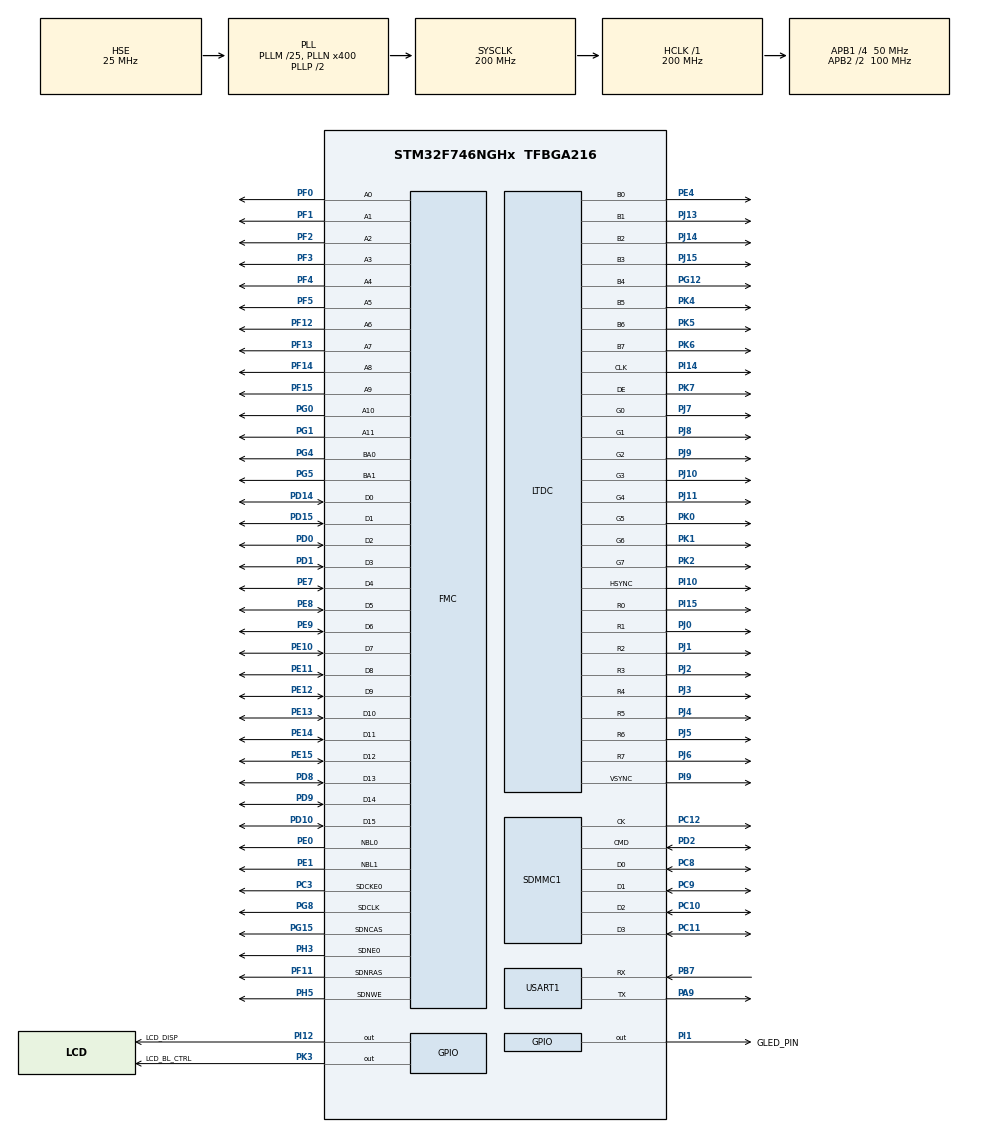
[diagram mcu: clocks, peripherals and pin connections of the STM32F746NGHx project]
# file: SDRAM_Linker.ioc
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CORTEX_M7.ART_ACCLERATOR_ENABLE=0
CORTEX_M7.AccessPermission-Cortex_Memory_Protection_Unit_Region0_Settings=MPU_REGION_FULL_ACCESS
CORTEX_M7.AccessPermission-Cortex_Memory_Protection_Unit_Region1_Settings=MPU_REGION_FULL_ACCESS
CORTEX_M7.AccessPermission-Cortex_Memory_Protection_Unit_Region2_Settings=MPU_REGION_FULL_ACCESS
CORTEX_M7.BaseAddress-Cortex_Memory_Protection_Unit_Region0_Settings=0xC0000000
CORTEX_M7.BaseAddress-Cortex_Memory_Protection_Unit_Region1_Settings=0xC0000000
CORTEX_M7.BaseAddress-Cortex_Memory_Protection_Unit_Region2_Settings=0xC0200000
CORTEX_M7.CPU_DCache=Enabled
CORTEX_M7.CPU_ICache=Enabled
CORTEX_M7.DisableExec-Cortex_Memory_Protection_Unit_Region1_Settings=MPU_INSTRUCTION_ACCESS_DISABLE
CORTEX_M7.DisableExec-Cortex_Memory_Protection_Unit_Region2_Settings=MPU_INSTRUCTION_ACCESS_DISABLE
CORTEX_M7.Enable-Cortex_Memory_Protection_Unit_Region0_Settings=MPU_REGION_ENABLE
CORTEX_M7.Enable-Cortex_Memory_Protection_Unit_Region1_Settings=MPU_REGION_ENABLE
CORTEX_M7.Enable-Cortex_Memory_Protection_Unit_Region2_Settings=MPU_REGION_ENABLE
CORTEX_M7.IsBufferable-Cortex_Memory_Protection_Unit_Region0_Settings=MPU_ACCESS_BUFFERABLE
CORTEX_M7.IsBufferable-Cortex_Memory_Protection_Unit_Region1_Settings=MPU_ACCESS_BUFFERABLE
CORTEX_M7.IsBufferable-Cortex_Memory_Protection_Unit_Region2_Settings=MPU_ACCESS_BUFFERABLE
CORTEX_M7.IsCacheable-Cortex_Memory_Protection_Unit_Region0_Settings=MPU_ACCESS_CACHEABLE
CORTEX_M7.IsCacheable-Cortex_Memory_Protection_Unit_Region1_Settings=MPU_ACCESS_CACHEABLE
CORTEX_M7.IsCacheable-Cortex_Memory_Protection_Unit_Region2_Settings=MPU_ACCESS_CACHEABLE
CORTEX_M7.MPU_Control=MPU_PRIVILEGED_DEFAULT
CORTEX_M7.Size-Cortex_Memory_Protection_Unit_Region0_Settings=MPU_REGION_SIZE_8MB
CORTEX_M7.Size-Cortex_Memory_Protection_Unit_Region1_Settings=MPU_REGION_SIZE_512KB
CORTEX_M7.Size-Cortex_Memory_Protection_Unit_Region2_Settings=MPU_REGION_SIZE_512KB
CORTEX_M7.TypeExtField-Cortex_Memory_Protection_Unit_Region0_Settings=MPU_TEX_LEVEL0
CORTEX_M7.TypeExtField-Cortex_Memory_Protection_Unit_Region1_Settings=MPU_TEX_LEVEL0
Dma.Request0=SDMMC1_RX
Dma.Request1=SDMMC1_TX
Dma.SDMMC1_RX.0.Direction=DMA_PERIPH_TO_MEMORY
Dma.SDMMC1_RX.0.FIFOMode=DMA_FIFOMODE_ENABLE
Dma.SDMMC1_RX.0.FIFOThreshold=DMA_FIFO_THRESHOLD_FULL
Dma.SDMMC1_RX.0.Instance=DMA2_Stream3
Dma.SDMMC1_RX.0.MemBurst=DMA_MBURST_INC4
Dma.SDMMC1_RX.0.MemDataAlignment=DMA_MDATAALIGN_WORD
Dma.SDMMC1_RX.0.MemInc=DMA_MINC_ENABLE
Dma.SDMMC1_RX.0.Mode=DMA_PFCTRL
Dma.SDMMC1_RX.0.PeriphBurst=DMA_PBURST_INC4
Dma.SDMMC1_RX.0.PeriphDataAlignment=DMA_PDATAALIGN_WORD
Dma.SDMMC1_RX.0.PeriphInc=DMA_PINC_DISABLE
Dma.SDMMC1_RX.0.Priority=DMA_PRIORITY_LOW
Dma.SDMMC1_TX.1.Direction=DMA_MEMORY_TO_PERIPH
Dma.SDMMC1_TX.1.FIFOMode=DMA_FIFOMODE_ENABLE
Dma.SDMMC1_TX.1.FIFOThreshold=DMA_FIFO_THRESHOLD_FULL
Dma.SDMMC1_TX.1.Instance=DMA2_Stream6
Dma.SDMMC1_TX.1.MemBurst=DMA_MBURST_INC4
Dma.SDMMC1_TX.1.MemDataAlignment=DMA_MDATAALIGN_WORD
Dma.SDMMC1_TX.1.MemInc=DMA_MINC_ENABLE
Dma.SDMMC1_TX.1.Mode=DMA_PFCTRL
Dma.SDMMC1_TX.1.PeriphBurst=DMA_PBURST_INC4
Dma.SDMMC1_TX.1.PeriphDataAlignment=DMA_PDATAALIGN_WORD
Dma.SDMMC1_TX.1.PeriphInc=DMA_PINC_DISABLE
Dma.SDMMC1_TX.1.Priority=DMA_PRIORITY_LOW
FATFS._FS_RPATH=1
FATFS._MAX_SS=4096
FMC.CASLatency1=FMC_SDRAM_CAS_LATENCY_2
FMC.ExitSelfRefreshDelay1=6
FMC.LoadToActiveDelay1=2
FMC.RCDDelay1=2
FMC.RPDelay1=2
FMC.ReadBurst1=FMC_SDRAM_RBURST_ENABLE
FMC.RowCycleDelay1=6
FMC.SDClockPeriod1=FMC_SDRAM_CLOCK_PERIOD_2
FMC.SelfRefreshTime1=4
FMC.WriteRecoveryTime1=2
LIBJPEG.RGB_ORDERING=RGB
LTDC.ActiveH=272
LTDC.ActiveW=480
LTDC.Alpha_L0=255
LTDC.Alpha_L1=255
LTDC.BlendingFactor1_L0=LTDC_BLENDING_FACTOR1_PAxCA
LTDC.BlendingFactor1_L1=LTDC_BLENDING_FACTOR1_PAxCA
LTDC.BlendingFactor2_L0=LTDC_BLENDING_FACTOR2_PAxCA
LTDC.BlendingFactor2_L1=LTDC_BLENDING_FACTOR2_PAxCA
LTDC.FBStartAdress_L0=0xC0000000
LTDC.FBStartAdress_L1=0xC0200000
LTDC.HBP=13
LTDC.HFP=32
LTDC.HSync=41
LTDC.ImageHeight_L0=272
LTDC.ImageHeight_L1=272
LTDC.ImageWidth_L0=480
LTDC.ImageWidth_L1=480
LTDC.Layers=1
LTDC.PixelFormat_L0=LTDC_PIXEL_FORMAT_ARGB8888
LTDC.VSync=10
LTDC.WindowX1_L0=480
LTDC.WindowX1_L1=480
LTDC.WindowY1_L0=272
LTDC.WindowY1_L1=272
Mcu.Family=STM32F7
Mcu.Name=STM32F746NGHx
Mcu.Package=TFBGA216
NVIC.DMA2_Stream3_IRQn=true\:0\:0\:false\:false\:true\:false\:true
NVIC.DMA2_Stream6_IRQn=true\:0\:0\:false\:false\:true\:false\:true
NVIC.PriorityGroup=NVIC_PRIORITYGROUP_4
NVIC.SDMMC1_IRQn=true\:0\:0\:false\:false\:true\:true\:true
PA13.Mode=Serial_Wire
PA13.Signal=SYS_JTMS-SWDIO
PA14.Mode=Serial_Wire
PA14.Signal=SYS_JTCK-SWCLK
PA9.Mode=Asynchronous
PA9.Signal=USART1_TX
PB7.Mode=Asynchronous
PB7.Signal=USART1_RX
PC10.Mode=SD_4_bits_Wide_bus
PC10.Signal=SDMMC1_D2
PC11.Mode=SD_4_bits_Wide_bus
PC11.Signal=SDMMC1_D3
PC12.Mode=SD_4_bits_Wide_bus
PC12.Signal=SDMMC1_CK
PC3.Mode=SdramChipSelect1_1
PC3.Signal=FMC_SDCKE0
PC8.Mode=SD_4_bits_Wide_bus
PC8.Signal=SDMMC1_D0
PC9.Mode=SD_4_bits_Wide_bus
PC9.Signal=SDMMC1_D1
PD0.Signal=FMC_D2_DA2
PD1.Signal=FMC_D3_DA3
PD10.Signal=FMC_D15_DA15
PD14.Signal=FMC_D0_DA0
PD15.Signal=FMC_D1_DA1
PD2.Mode=SD_4_bits_Wide_bus
PD2.Signal=SDMMC1_CMD
PD8.Signal=FMC_D13_DA13
PD9.Signal=FMC_D14_DA14
PE0.Signal=FMC_NBL0
PE1.Signal=FMC_NBL1
PE10.Signal=FMC_D7_DA7
PE11.Signal=FMC_D8_DA8
PE12.Signal=FMC_D9_DA9
PE13.Signal=FMC_D10_DA10
PE14.Signal=FMC_D11_DA11
PE15.Signal=FMC_D12_DA12
PE4.GPIO_Speed=GPIO_SPEED_FREQ_HIGH
PE4.Mode=RGB888
PE4.Signal=LTDC_B0
PE7.Signal=FMC_D4_DA4
PE8.Signal=FMC_D5_DA5
PE9.Signal=FMC_D6_DA6
PF0.Signal=FMC_A0
PF1.Signal=FMC_A1
PF11.Signal=FMC_SDNRAS
PF12.Signal=FMC_A6
PF13.Signal=FMC_A7
PF14.Signal=FMC_A8
PF15.Signal=FMC_A9
PF2.Signal=FMC_A2
PF3.Signal=FMC_A3
PF4.Signal=FMC_A4
PF5.Signal=FMC_A5
PG0.Signal=FMC_A10
PG1.Signal=FMC_A11
PG12.GPIO_Speed=GPIO_SPEED_FREQ_HIGH
PG12.Mode=RGB888
PG12.Signal=LTDC_B4
PG15.Signal=FMC_SDNCAS
PG4.Signal=FMC_A14_BA0
PG5.Signal=FMC_A15_BA1
PG8.Signal=FMC_SDCLK
PH0/OSC_IN.Mode=HSE-External-Oscillator
PH0/OSC_IN.Signal=RCC_OSC_IN
PH1/OSC_OUT.Mode=HSE-External-Oscillator
PH1/OSC_OUT.Signal=RCC_OSC_OUT
PH3.Mode=SdramChipSelect1_1
PH3.Signal=FMC_SDNE0
PH5.Signal=FMC_SDNWE
PI1.GPIO_Label=GLED_PIN
PI1.PinState=GPIO_PIN_RESET
PI1.Signal=GPIO_Output
PI10.GPIO_Speed=GPIO_SPEED_FREQ_HIGH
PI10.Mode=RGB888
PI10.Signal=LTDC_HSYNC
PI12.GPIO_Label=LCD_DISP
PI12.GPIO_Speed=GPIO_SPEED_FREQ_HIGH
PI12.PinState=GPIO_PIN_SET
PI12.Signal=GPIO_Output
PI14.GPIO_Speed=GPIO_SPEED_FREQ_HIGH
PI14.Mode=RGB888
PI14.Signal=LTDC_CLK
PI15.GPIO_Speed=GPIO_SPEED_FREQ_HIGH
PI15.Mode=RGB888
PI15.Signal=LTDC_R0
PI9.GPIO_Speed=GPIO_SPEED_FREQ_HIGH
PI9.Mode=RGB888
PI9.Signal=LTDC_VSYNC
PJ0.GPIO_Speed=GPIO_SPEED_FREQ_HIGH
PJ0.Mode=RGB888
PJ0.Signal=LTDC_R1
PJ1.GPIO_Speed=GPIO_SPEED_FREQ_HIGH
PJ1.Mode=RGB888
PJ1.Signal=LTDC_R2
PJ10.GPIO_Speed=GPIO_SPEED_FREQ_HIGH
PJ10.Mode=RGB888
PJ10.Signal=LTDC_G3
PJ11.GPIO_Speed=GPIO_SPEED_FREQ_HIGH
PJ11.Mode=RGB888
PJ11.Signal=LTDC_G4
PJ13.GPIO_Speed=GPIO_SPEED_FREQ_HIGH
PJ13.Mode=RGB888
PJ13.Signal=LTDC_B1
PJ14.GPIO_Speed=GPIO_SPEED_FREQ_HIGH
PJ14.Mode=RGB888
PJ14.Signal=LTDC_B2
PJ15.GPIO_Speed=GPIO_SPEED_FREQ_HIGH
PJ15.Mode=RGB888
PJ15.Signal=LTDC_B3
PJ2.GPIO_Speed=GPIO_SPEED_FREQ_HIGH
PJ2.Mode=RGB888
PJ2.Signal=LTDC_R3
PJ3.GPIO_Speed=GPIO_SPEED_FREQ_HIGH
PJ3.Mode=RGB888
PJ3.Signal=LTDC_R4
PJ4.GPIO_Speed=GPIO_SPEED_FREQ_HIGH
PJ4.Mode=RGB888
PJ4.Signal=LTDC_R5
PJ5.GPIO_Speed=GPIO_SPEED_FREQ_HIGH
PJ5.Mode=RGB888
PJ5.Signal=LTDC_R6
PJ6.GPIO_Speed=GPIO_SPEED_FREQ_HIGH
PJ6.Mode=RGB888
PJ6.Signal=LTDC_R7
PJ7.GPIO_Speed=GPIO_SPEED_FREQ_HIGH
PJ7.Mode=RGB888
PJ7.Signal=LTDC_G0
PJ8.GPIO_Speed=GPIO_SPEED_FREQ_HIGH
PJ8.Mode=RGB888
PJ8.Signal=LTDC_G1
PJ9.GPIO_Speed=GPIO_SPEED_FREQ_HIGH
PJ9.Mode=RGB888
PJ9.Signal=LTDC_G2
PK0.GPIO_Speed=GPIO_SPEED_FREQ_HIGH
PK0.Mode=RGB888
PK0.Signal=LTDC_G5
PK1.GPIO_Speed=GPIO_SPEED_FREQ_HIGH
PK1.Mode=RGB888
PK1.Signal=LTDC_G6
PK2.GPIO_Speed=GPIO_SPEED_FREQ_HIGH
PK2.Mode=RGB888
PK2.Signal=LTDC_G7
PK3.GPIO_Label=LCD_BL_CTRL
PK3.GPIO_Speed=GPIO_SPEED_FREQ_HIGH
PK3.PinState=GPIO_PIN_SET
PK3.Signal=GPIO_Output
PK4.GPIO_Speed=GPIO_SPEED_FREQ_HIGH
PK4.Mode=RGB888
PK4.Signal=LTDC_B5
PK5.GPIO_Speed=GPIO_SPEED_FREQ_HIGH
PK5.Mode=RGB888
PK5.Signal=LTDC_B6
PK6.GPIO_Speed=GPIO_SPEED_FREQ_HIGH
PK6.Mode=RGB888
PK6.Signal=LTDC_B7
PK7.GPIO_Speed=GPIO_SPEED_FREQ_HIGH
PK7.Mode=RGB888
PK7.Signal=LTDC_DE
ProjectManager.HeapSize=0x2000
ProjectManager.StackSize=0x4000
ProjectManager.TargetToolchain=Other Toolchains (GPDSC)
RCC.AHBFreq_Value=200000000
RCC.APB1CLKDivider=RCC_HCLK_DIV4
RCC.APB1Freq_Value=50000000
RCC.APB1TimFreq_Value=100000000
RCC.APB2CLKDivider=RCC_HCLK_DIV2
RCC.APB2Freq_Value=100000000
RCC.APB2TimFreq_Value=200000000
RCC.CortexFreq_Value=200000000
RCC.HCLKFreq_Value=200000000
RCC.HSE_VALUE=25000000
RCC.HSI_VALUE=16000000
RCC.LSE_VALUE=32768
RCC.PLL48CLockSelection=RCC_CLK48SOURCE_PLLSAIP
RCC.PLLM=25
RCC.PLLN=400
RCC.PLLSAIN=100
RCC.PLLSAIR=5
RCC.PLLSourceVirtual=RCC_PLLSOURCE_HSE
RCC.SDMMCClockSelection=RCC_SDMMC1CLKSOURCE_CLK48
RCC.SYSCLKFreq_VALUE=200000000
RCC.SYSCLKSource=RCC_SYSCLKSOURCE_PLLCLK
RCC.USBFreq_Value=50000000
RCC.VCOOutputFreq_Value=400000000
SH.FMC_A0.0=FMC_A0,12b-sda1
SH.FMC_A1.0=FMC_A1,12b-sda1
SH.FMC_A10.0=FMC_A10,12b-sda1
SH.FMC_A11.0=FMC_A11,12b-sda1
SH.FMC_A14_BA0.0=FMC_BA0,FourSdramBanks1
SH.FMC_A15_BA1.0=FMC_BA1,FourSdramBanks1
SH.FMC_A2.0=FMC_A2,12b-sda1
SH.FMC_A3.0=FMC_A3,12b-sda1
SH.FMC_A4.0=FMC_A4,12b-sda1
SH.FMC_A5.0=FMC_A5,12b-sda1
SH.FMC_A6.0=FMC_A6,12b-sda1
SH.FMC_A7.0=FMC_A7,12b-sda1
SH.FMC_A8.0=FMC_A8,12b-sda1
SH.FMC_A9.0=FMC_A9,12b-sda1
SH.FMC_D0_DA0.0=FMC_D0,sd-16b-d1
SH.FMC_D10_DA10.0=FMC_D10,sd-16b-d1
SH.FMC_D11_DA11.0=FMC_D11,sd-16b-d1
SH.FMC_D12_DA12.0=FMC_D12,sd-16b-d1
SH.FMC_D13_DA13.0=FMC_D13,sd-16b-d1
SH.FMC_D14_DA14.0=FMC_D14,sd-16b-d1
SH.FMC_D15_DA15.0=FMC_D15,sd-16b-d1
SH.FMC_D1_DA1.0=FMC_D1,sd-16b-d1
SH.FMC_D2_DA2.0=FMC_D2,sd-16b-d1
SH.FMC_D3_DA3.0=FMC_D3,sd-16b-d1
SH.FMC_D4_DA4.0=FMC_D4,sd-16b-d1
SH.FMC_D5_DA5.0=FMC_D5,sd-16b-d1
SH.FMC_D6_DA6.0=FMC_D6,sd-16b-d1
SH.FMC_D7_DA7.0=FMC_D7,sd-16b-d1
SH.FMC_D8_DA8.0=FMC_D8,sd-16b-d1
SH.FMC_D9_DA9.0=FMC_D9,sd-16b-d1
SH.FMC_NBL0.0=FMC_NBL0,Sd2ByteEnable1
SH.FMC_NBL1.0=FMC_NBL1,Sd2ByteEnable1
SH.FMC_SDCLK.0=FMC_SDCLK,12b-sda1
SH.FMC_SDNCAS.0=FMC_SDNCAS,12b-sda1
SH.FMC_SDNRAS.0=FMC_SDNRAS,12b-sda1
SH.FMC_SDNWE.0=FMC_SDNWE,12b-sda1
USART1.VirtualMode-Asynchronous=VM_ASYNC
VP_FATFS_VS_SDIO.Mode=SDIO
VP_LIBJPEG_VS_JPEGLIB.Mode=Enabled
board=custom

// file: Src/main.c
/* USER CODE BEGIN Header */
/**
  ******************************************************************************
  * @file           : main.c
  * @brief          : Main program body
  ******************************************************************************
  * @attention
  *
  * <h2><center>&copy; Copyright (c) 2020 STMicroelectronics.
  * All rights reserved.</center></h2>
  *
  * This software component is licensed by ST under Ultimate Liberty license
  * SLA0044, the "License"; You may not use this file except in compliance with
  * the License. You may obtain a copy of the License at:
  *                             www.st.com/SLA0044
  *
  ******************************************************************************
  */
/* USER CODE END Header */

#include "main.h"
#include "dma.h"
#include "fatfs.h"
#include "ltdc.h"
#include "sdmmc.h"
#include "usart.h"
#include "gpio.h"
#include "fmc.h"

/* USER CODE BEGIN Includes */

#include "lodepng.h"
#include "decode.h"
#include "jpeglib.h"
#include "libjpeg.h"

/* USER CODE END Includes */

/* USER CODE BEGIN PTD */
typedef struct
{
	FATFS SDFatFs;
	FIL MyFile;
	FRESULT res;
	uint32_t byteswritten;
	uint32_t bytesread;
}SD;
/* User defined device identifier */

/* USER CODE END PTD */

/* USER CODE BEGIN PV */

#define PNG_COUNT 29
PNG_PicTypedef Image[PNG_COUNT];
SD sdcard;
RGB_typedef *RGB_matrix;
uint8_t   _aucLine[2048];
uint32_t  offset = 0;
uint32_t line_counter = 271;

/* USER CODE END PV */

void SystemClock_Config(void);
static void MPU_Config(void);
/* USER CODE BEGIN PFP */
static uint8_t Jpeg_CallbackFunction(uint8_t* Row, uint32_t DataLength);
static void OpenBMP(uint8_t *ptr, const char* fname);
static uint32_t OpenPNG(uint8_t *ptr, const char* fname);
static uint8_t DecodePNG(char* filename, uint8_t imagenumber);
/* USER CODE END PFP */

int main(void)
{

  /* MPU Configuration--------------------------------------------------------*/
  MPU_Config();

  /* Enable I-Cache---------------------------------------------------------*/
  SCB_EnableICache();

  /* Enable D-Cache---------------------------------------------------------*/
  SCB_EnableDCache();

  /* MCU Configuration--------------------------------------------------------*/

  /* Reset of all peripherals, Initializes the Flash interface and the Systick. */
  HAL_Init();

  /* Configure the system clock */
  SystemClock_Config();

  /* Initialize all configured peripherals */
  MX_GPIO_Init();
  MX_DMA_Init();
  MX_LTDC_Init();
  MX_FMC_Init();
  MX_SDMMC1_SD_Init();
  MX_FATFS_Init();
  MX_USART1_UART_Init();
  /* USER CODE BEGIN 2 */

	/*External SDRAM initialization*/
	MT48LC4M32B2_Init(&hsdram1);

	/*FatFS DISC MOUNTING*/
	if (f_mount(&sdcard.SDFatFs, "0", 0) != FR_OK)
	{
		HAL_UART_Transmit(&huart1, (uint8_t*)"Disk Mount - ERROR!\n", 20, 500);
		Error_Handler();
	}
	else
	{
		HAL_UART_Transmit(&huart1, (uint8_t*)"Disk Mount - OK!\n", 17, 500);
	}

	TFT_FillScreen(0, 0);/*Clear screen*/
	TFT_FillScreen(0, 1);

#if 0
	/*BMP picture drawing*/
	uint8_t* bmp_buffer = (uint8_t*)malloc(600000*sizeof(uint8_t));
	OpenBMP(bmp_buffer, "SLZ.bmp");
	TFT_DrawBitmap(0, 0, bmp_buffer, 0);
	free(bmp_buffer);
#endif

	f_chdir("JPG");/*CD to JPG directory*/
	if (f_open(&sdcard.MyFile, "1.jpg", FA_READ) == FR_OK)
	{
		jpeg_decode(&sdcard.MyFile, IMAGE_WIDTH, _aucLine, Jpeg_CallbackFunction);
	}
	else
	{
		HAL_UART_Transmit(&huart1, (uint8_t*)"JPG - ERROR\n", 12, 500);
	}

	f_close(&sdcard.MyFile);
	f_chdir("/"); /*Back to root path*/

	if (DecodePNG("R.png", 28) != 1)
	{
		TFT_DrawRawPicture(0, 0, Image[28].width, Image[28].height, Image[28].storage, 1);
	}
	else
	{
		HAL_UART_Transmit(&huart1, (uint8_t*)"PNG - ERROR\n", 12, 500);
	}
	//free(Image[1].storage);
	TFT_SetFont(&Font24);
	TFT_SetColor(LCD_COLOR_RED);
	TFT_DisplayString(375, 5, (uint8_t*)"demo 3", LEFT_MODE, 1);
	TFT_SetFont(&Font20);
	TFT_SetColor(LCD_COLOR_YELLOW);
	TFT_DisplayString(370, 255, (uint8_t*)"30.04.20", LEFT_MODE, 1);

	f_chdir("GIF");
	char name[6] = { 0 };
	for (uint8_t i = 0; i < 24; i++)/*GIF png frames decoding*/
	{
		sprintf(name, "%d.png", i);
		DecodePNG(name, i);
	}

  /* USER CODE END 2 */

  /* Infinite loop */
  /* USER CODE BEGIN WHILE */

  while(1)
	{
		for (uint8_t i = 0; i < 22; i++)
		{
			TFT_DrawRawPicture(170, 50, Image[i].width, Image[i].height, Image[i].storage, 1);
			HAL_Delay(35);
			/*Future FreeRTOS Task!*/
		}

	}

}
    /* USER CODE END WHILE */

    /* USER CODE BEGIN 3 */
/*Decode PNG into Image[imagenumber].storage field of Image Structure*/
static uint8_t DecodePNG(char* filename, uint8_t imagenumber)
{
	uint8_t* png_buffer = (uint8_t*)malloc(100000 * sizeof(uint8_t));
	/*Write png picture to sdram buffer and assign its size to field of Image structure*/
	Image[imagenumber].size = OpenPNG(png_buffer, filename);

	if (Image[imagenumber].size == 1) return 1;/*OpenPNG() ERROR*/

	/*Decode png to storage field of Image structure*/
	Image[imagenumber].error = lodepng_decode32(&Image[imagenumber].storage,
		&Image[imagenumber].width,
		&Image[imagenumber].height,
		png_buffer,
		Image[imagenumber].size);

	if (Image[1].error)
	{
		/*DECODING ERROR*/
		sprintf(Image[imagenumber].ErrorStr, "error %u: %s\n",
			Image[imagenumber].error,
			lodepng_error_text(Image[imagenumber].error));

		HAL_UART_Transmit(&huart1,
			(uint8_t*)Image[imagenumber].ErrorStr,
			sizeof(Image[imagenumber].ErrorStr),
			500);
	}
	free(png_buffer);
	return 0;
}

/*Write png from SD card to sdram buffer, and return its size in Bytes;
Return 1 if something goes wrong **/
static uint32_t OpenPNG(uint8_t *ptr, const char* fname)
{

		uint8_t sector[4096];
		uint32_t  size = 0, i1 = 0, ind1 = 0, pngsize = 0;
		const char PNGsign[8] = "504e47\n";/*True sign of png image*/
		char Sign[7] = { 0 };/*buffer for current sign*/
		char FileSize[25] = { 0 };

		if (f_open(&sdcard.MyFile, fname, FA_READ) != FR_OK)

		{
			HAL_UART_Transmit(&huart1, (uint8_t*)"Error!!\n", 8, 1000);
		}
		else
		{
			size = (uint32_t)f_size(&sdcard.MyFile);
			pngsize = size;
			sprintf(FileSize, "PNG size: %lu B\n", size);
			HAL_UART_Transmit(&huart1, (uint8_t*)"\nOpen Image - OK!\n", 18, 1000);
			HAL_UART_Transmit(&huart1, (uint8_t*)FileSize, 18, 1000);
			if (f_read(&sdcard.MyFile, sector, 4, (UINT *)sdcard.bytesread) != FR_OK)
			{
				HAL_UART_Transmit(&huart1, (uint8_t*)"\nReading - ERROR!\n", 18, 1000);
				Error_Handler();
			}
			else
			{
				sprintf(Sign, "%x%x%x\n", sector[1], sector[2], sector[3]);
				if (!(strcmp(PNGsign, Sign)))
				{
					HAL_UART_Transmit(&huart1, (uint8_t*)"Sign - OK!\n", 11, 1000);
					do
					{
						if (size < 4096)
						{
							i1 = size;
						}
						else
						{
							i1 = 4096;
						}
						size -= i1;
						f_lseek(&sdcard.MyFile, ind1);
						f_read(&sdcard.MyFile, sector, i1, (UINT *)&sdcard.bytesread);
						memcpy((void*)(ptr + ind1), (void*)sector, i1);
						ind1 += i1;
					} while (size > 0);
					HAL_UART_Transmit(&huart1, (uint8_t*)"PNG was loaded into png_buffer! \n", 33, 1000);
					f_close(&sdcard.MyFile);
				}
				else
				{
					return 1;/*It isn't PNG file*/
				}
				ind1 = 0;
			}
		}
		return pngsize;
	}
static void OpenBMP(uint8_t *ptr, const char* fname)
{

		uint32_t  sz = 0, i1 = 0, ind1 = 0;
		static uint32_t bmp_addr;
		char FileSize[25] = { 0 };
		uint8_t sect[4096];

		if (f_open(&sdcard.MyFile, fname, FA_READ) != FR_OK)

		{
			HAL_UART_Transmit(&huart1, (uint8_t*)"Open Image - ERROR!\\n", 20, 1000);
		}

		else
		{
			sz = (uint32_t)f_size(&sdcard.MyFile);
			sprintf(FileSize, "BMP size: %lu B\n", sz);
			HAL_UART_Transmit(&huart1, (uint8_t*)"Open Image - OK!\n", 17, 1000);
			HAL_UART_Transmit(&huart1, (uint8_t*)FileSize, 20, 1000);
			if (f_read(&sdcard.MyFile, sect, 30, (UINT *)sdcard.bytesread) != FR_OK)
			{
				Error_Handler();
			}
			else
			{
				bmp_addr = (uint32_t)sect;
				sz = *(uint16_t *)(bmp_addr + 2);
				sz |= (*(uint16_t *)(bmp_addr + 4)) << 16;

				do
				{
					if (sz < 4096)
					{
						i1 = sz;
					}
					else
					{
						i1 = 4096;
					}
					sz -= i1;
					f_lseek(&sdcard.MyFile, ind1);
					f_read(&sdcard.MyFile, sect, i1, (UINT *)&sdcard.bytesread);
					memcpy((void*)(ptr + ind1), (void*)sect, i1);
					ind1 += i1;
				} while (sz > 0);
				f_close(&sdcard.MyFile);
			}
			ind1 = 0;
		}
	}

static uint8_t Jpeg_CallbackFunction(uint8_t* Row, uint32_t DataLength)
{
	/*DRAW JPG PICTURE ON LAYER0*/
	RGB_matrix =  (RGB_typedef*)Row;
	uint32_t  ARGB32Buffer[IMAGE_WIDTH];

	for (uint32_t ix = 0; ix < IMAGE_WIDTH; ix++)
	{
		ARGB32Buffer[ix]  = (uint32_t)
		(
		 ((RGB_matrix[ix].B << 16) |
		  (RGB_matrix[ix].G << 8) |
		  (RGB_matrix[ix].R) | 0xFF000000)
		);

		*(__IO uint32_t *)(hltdc.LayerCfg[0].FBStartAdress + (ix * 4) + (IMAGE_WIDTH * (IMAGE_HEIGHT - line_counter - 1) * 4)) = ARGB32Buffer[ix];
	}

#ifdef SWAP_RB
	uint32_t pixel = 0, width_counter, result = 0, result1 = 0;

	for (width_counter = 0; width_counter < IMAGE_WIDTH; width_counter++)
	{
		pixel = *(__IO uint32_t *)(LCD_FRAME_BUFFER + (width_counter * 4) + (IMAGE_WIDTH * (IMAGE_HEIGHT - line_counter - 1) * 4));
		result1 = (((pixel & 0x00FF0000) >> 16) | ((pixel & 0x000000FF) << 16));
		pixel = pixel & 0xFF00FF00;
		result = (result1 | pixel);
		*(__IO uint32_t *)(LCD_FRAME_BUFFER + (width_counter * 4) + (IMAGE_WIDTH * (IMAGE_HEIGHT - line_counter - 1) * 4)) = result;

	}
#endif

	line_counter--;
	return 0;
}
  /* USER CODE END 3 */

void SystemClock_Config(void)
{
  RCC_OscInitTypeDef RCC_OscInitStruct = {0};
  RCC_ClkInitTypeDef RCC_ClkInitStruct = {0};
  RCC_PeriphCLKInitTypeDef PeriphClkInitStruct = {0};

  /** Configure the main internal regulator output voltage
  */
  __HAL_RCC_PWR_CLK_ENABLE();
  __HAL_PWR_VOLTAGESCALING_CONFIG(PWR_REGULATOR_VOLTAGE_SCALE1);
  /** Initializes the CPU, AHB and APB busses clocks
  */
  RCC_OscInitStruct.OscillatorType = RCC_OSCILLATORTYPE_HSE;
  RCC_OscInitStruct.HSEState = RCC_HSE_ON;
  RCC_OscInitStruct.PLL.PLLState = RCC_PLL_ON;
  RCC_OscInitStruct.PLL.PLLSource = RCC_PLLSOURCE_HSE;
  RCC_OscInitStruct.PLL.PLLM = 25;
  RCC_OscInitStruct.PLL.PLLN = 400;
  RCC_OscInitStruct.PLL.PLLP = RCC_PLLP_DIV2;
  RCC_OscInitStruct.PLL.PLLQ = 2;
  if (HAL_RCC_OscConfig(&RCC_OscInitStruct) != HAL_OK)
  {
    Error_Handler();
  }
  /** Activate the Over-Drive mode
  */
  if (HAL_PWREx_EnableOverDrive() != HAL_OK)
  {
    Error_Handler();
  }
  /** Initializes the CPU, AHB and APB busses clocks
  */
  RCC_ClkInitStruct.ClockType = RCC_CLOCKTYPE_HCLK|RCC_CLOCKTYPE_SYSCLK
                              |RCC_CLOCKTYPE_PCLK1|RCC_CLOCKTYPE_PCLK2;
  RCC_ClkInitStruct.SYSCLKSource = RCC_SYSCLKSOURCE_PLLCLK;
  RCC_ClkInitStruct.AHBCLKDivider = RCC_SYSCLK_DIV1;
  RCC_ClkInitStruct.APB1CLKDivider = RCC_HCLK_DIV4;
  RCC_ClkInitStruct.APB2CLKDivider = RCC_HCLK_DIV2;

  if (HAL_RCC_ClockConfig(&RCC_ClkInitStruct, FLASH_LATENCY_6) != HAL_OK)
  {
    Error_Handler();
  }
  PeriphClkInitStruct.PeriphClockSelection = RCC_PERIPHCLK_LTDC|RCC_PERIPHCLK_USART1
                              |RCC_PERIPHCLK_SDMMC1|RCC_PERIPHCLK_CLK48;
  PeriphClkInitStruct.PLLSAI.PLLSAIN = 100;
  PeriphClkInitStruct.PLLSAI.PLLSAIR = 5;
  PeriphClkInitStruct.PLLSAI.PLLSAIQ = 2;
  PeriphClkInitStruct.PLLSAI.PLLSAIP = RCC_PLLSAIP_DIV2;
  PeriphClkInitStruct.PLLSAIDivQ = 1;
  PeriphClkInitStruct.PLLSAIDivR = RCC_PLLSAIDIVR_2;
  PeriphClkInitStruct.Usart1ClockSelection = RCC_USART1CLKSOURCE_PCLK2;
  PeriphClkInitStruct.Clk48ClockSelection = RCC_CLK48SOURCE_PLLSAIP;
  PeriphClkInitStruct.Sdmmc1ClockSelection = RCC_SDMMC1CLKSOURCE_CLK48;
  if (HAL_RCCEx_PeriphCLKConfig(&PeriphClkInitStruct) != HAL_OK)
  {
    Error_Handler();
  }
}

/* MPU Configuration */

void MPU_Config(void)
{
  MPU_Region_InitTypeDef MPU_InitStruct = {0};

  /* Disables the MPU */
  HAL_MPU_Disable();
  /** Initializes and configures the Region and the memory to be protected
  */
  MPU_InitStruct.Enable = MPU_REGION_ENABLE;
  MPU_InitStruct.Number = MPU_REGION_NUMBER0;
  MPU_InitStruct.BaseAddress = 0xC0000000;
  MPU_InitStruct.Size = MPU_REGION_SIZE_8MB;
  MPU_InitStruct.SubRegionDisable = 0x0;
  MPU_InitStruct.TypeExtField = MPU_TEX_LEVEL0;
  MPU_InitStruct.AccessPermission = MPU_REGION_FULL_ACCESS;
  MPU_InitStruct.DisableExec = MPU_INSTRUCTION_ACCESS_ENABLE;
  MPU_InitStruct.IsShareable = MPU_ACCESS_NOT_SHAREABLE;
  MPU_InitStruct.IsCacheable = MPU_ACCESS_CACHEABLE;
  MPU_InitStruct.IsBufferable = MPU_ACCESS_BUFFERABLE;

  HAL_MPU_ConfigRegion(&MPU_InitStruct);
  /** Initializes and configures the Region and the memory to be protected
  */
  MPU_InitStruct.Enable = MPU_REGION_ENABLE;
  MPU_InitStruct.Number = MPU_REGION_NUMBER1;
  MPU_InitStruct.BaseAddress = 0xC0000000;
  MPU_InitStruct.Size = MPU_REGION_SIZE_512KB;
  MPU_InitStruct.SubRegionDisable = 0x0;
  MPU_InitStruct.TypeExtField = MPU_TEX_LEVEL0;
  MPU_InitStruct.AccessPermission = MPU_REGION_FULL_ACCESS;
  MPU_InitStruct.DisableExec = MPU_INSTRUCTION_ACCESS_DISABLE;
  MPU_InitStruct.IsShareable = MPU_ACCESS_NOT_SHAREABLE;
  MPU_InitStruct.IsCacheable = MPU_ACCESS_CACHEABLE;
  MPU_InitStruct.IsBufferable = MPU_ACCESS_BUFFERABLE;

  HAL_MPU_ConfigRegion(&MPU_InitStruct);
  /** Initializes and configures the Region and the memory to be protected
  */
  MPU_InitStruct.Enable = MPU_REGION_ENABLE;
  MPU_InitStruct.Number = MPU_REGION_NUMBER2;
  MPU_InitStruct.BaseAddress = 0xC0200000;
  MPU_InitStruct.Size = MPU_REGION_SIZE_512KB;
  MPU_InitStruct.SubRegionDisable = 0x0;
  MPU_InitStruct.TypeExtField = MPU_TEX_LEVEL0;
  MPU_InitStruct.AccessPermission = MPU_REGION_FULL_ACCESS;
  MPU_InitStruct.DisableExec = MPU_INSTRUCTION_ACCESS_DISABLE;
  MPU_InitStruct.IsShareable = MPU_ACCESS_NOT_SHAREABLE;
  MPU_InitStruct.IsCacheable = MPU_ACCESS_CACHEABLE;
  MPU_InitStruct.IsBufferable = MPU_ACCESS_BUFFERABLE;

  HAL_MPU_ConfigRegion(&MPU_InitStruct);
  /* Enables the MPU */
  HAL_MPU_Enable(MPU_PRIVILEGED_DEFAULT);

}

void Error_Handler(void)
{
}

/************************ (C) COPYRIGHT STMicroelectronics *****END OF FILE****/
